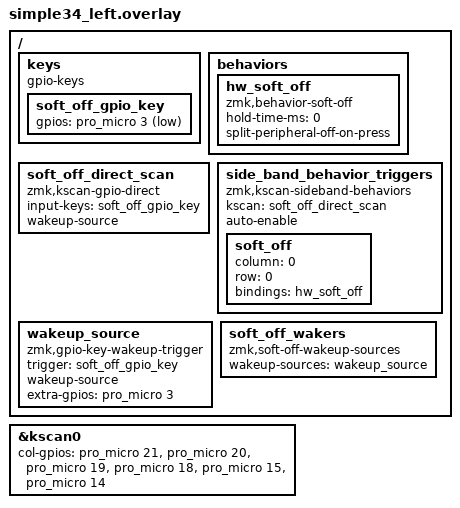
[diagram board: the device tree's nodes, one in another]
#include "simple34.dtsi"

/ {
    keys {
        compatible = "gpio-keys";
        /* Slide switch: P1 & P2 on VCC, P3 on GPIO
         * Switch ON: P3 connected to VCC -> HIGH -> awake
         * Switch OFF: P3 floating -> LOW (pull-down) -> soft-off
         */
        soft_off_gpio_key: soft_off_gpio_key {
            gpios = <&pro_micro 3 (GPIO_ACTIVE_LOW | GPIO_PULL_DOWN)>;
        };
    };

    behaviors {
        hw_soft_off: hw_soft_off {
            compatible = "zmk,behavior-soft-off";
            #binding-cells = <0>;
            hold-time-ms = <0>;
            split-peripheral-off-on-press;
        };
    };

    soft_off_direct_scan: soft_off_direct_scan {
        compatible = "zmk,kscan-gpio-direct";
        input-keys = <&soft_off_gpio_key>;
        wakeup-source;
    };

    side_band_behavior_triggers: side_band_behavior_triggers {
        compatible = "zmk,kscan-sideband-behaviors";
        kscan = <&soft_off_direct_scan>;
        auto-enable;

        soft_off {
            column = <0>;
            row = <0>;
            bindings = <&hw_soft_off>;
        };
    };

    wakeup_source: wakeup_source {
        compatible = "zmk,gpio-key-wakeup-trigger";
        trigger = <&soft_off_gpio_key>;
        wakeup-source;
        extra-gpios = <&pro_micro 3 GPIO_ACTIVE_HIGH>;
    };

    soft_off_wakers {
        compatible = "zmk,soft-off-wakeup-sources";
        wakeup-sources = <&wakeup_source>;
    };
};

&kscan0 {
    col-gpios
        = <&pro_micro 21 (GPIO_ACTIVE_HIGH)>
        , <&pro_micro 20 (GPIO_ACTIVE_HIGH)>
        , <&pro_micro 19 (GPIO_ACTIVE_HIGH)>
        , <&pro_micro 18 (GPIO_ACTIVE_HIGH)>
        , <&pro_micro 15 (GPIO_ACTIVE_HIGH)>
        , <&pro_micro 14 (GPIO_ACTIVE_HIGH)>
        ;       
};
